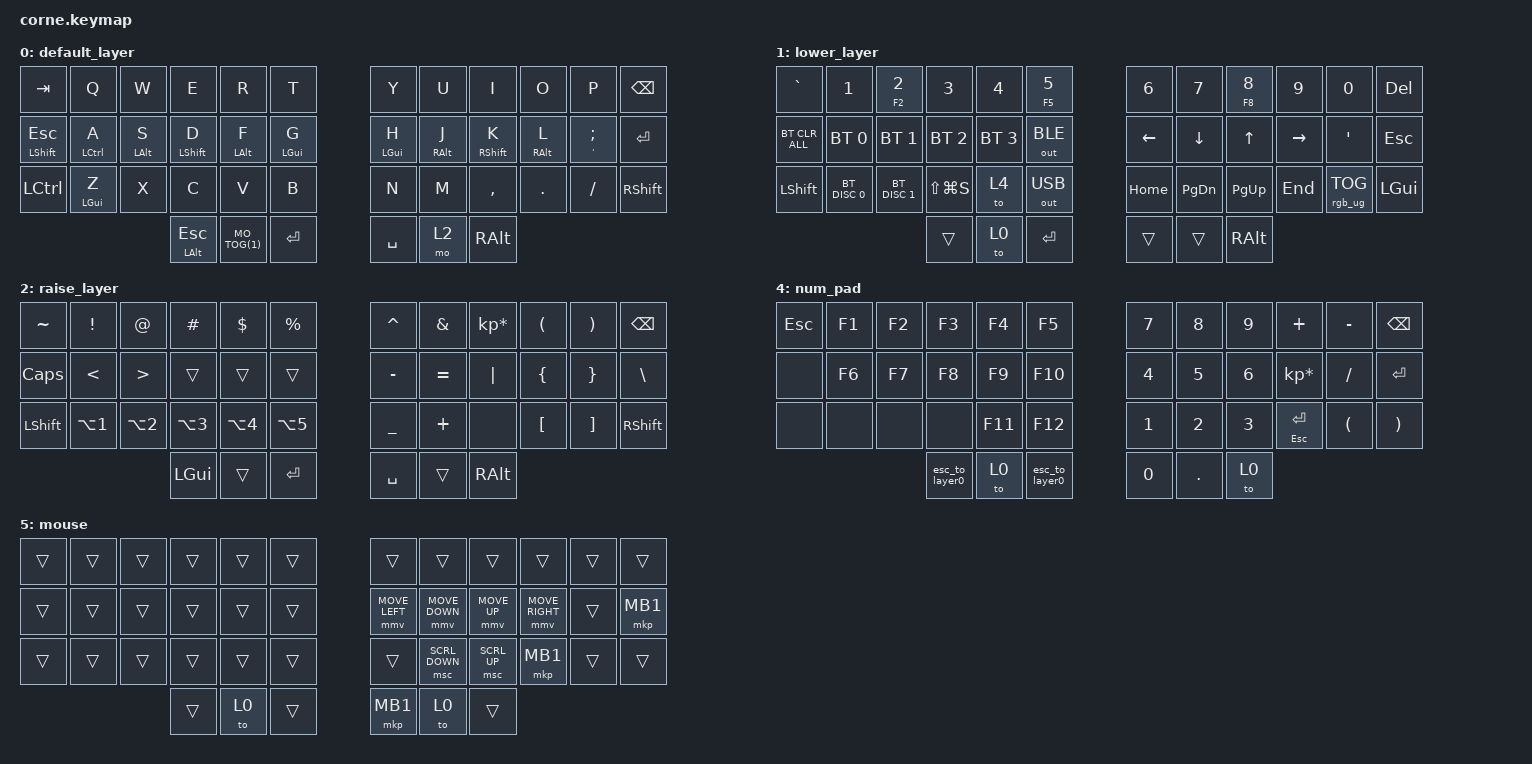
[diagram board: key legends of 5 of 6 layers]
/*
 * Copyright (c) 2020 The ZMK Contributors
 *
 * SPDX-License-Identifier: MIT
 */

#define ZMK_POINTING_DEFAULT_MOVE_VAL 1500  // default: 600
#define ZMK_POINTING_DEFAULT_SCRL_VAL 35    // default: 10

#include <behaviors.dtsi>
#include <dt-bindings/zmk/bt.h>
#include <dt-bindings/zmk/ext_power.h>
#include <dt-bindings/zmk/keys.h>
#include <dt-bindings/zmk/outputs.h>
#include <dt-bindings/zmk/pointing.h>
#include <dt-bindings/zmk/rgb.h>

#define MO_TOG(layer) &mo_tog layer layer   // Macro to apply momentary-layer-on-hold/toggle-layer-on-tap to a specific layer


&led_strip { chain-length = <27>; };

/ {
    behaviors {
        hm: homerow_mods {
            compatible = "zmk,behavior-hold-tap";
            #binding-cells = <2>;
            tapping-term-ms = <195>;
            quick-tap-ms = <100>;
            require-prior-idle-ms = <225>;
            flavor = "balanced";
            hold-trigger-on-release;
            bindings = <&kp>, <&kp>;
        };

        mo_tog: behavior_mo_tog {
            compatible = "zmk,behavior-hold-tap";
            #binding-cells = <2>;
            flavor = "hold-preferred";
            tapping-term-ms = <200>;
            bindings = <&mo>, <&tog>;
        };
                // &mo_tog 2 1     // &mo 2 on hold, &tog 1 on tap
                // MO_TOG(3)       // &mo 3 on hold, &tog 3 on tap
    };

    combos {
        compatible = "zmk,combos";

        controlLayer {
            bindings = <&to 3>;
            key-positions = <37 40>;
            timeout-ms = <250>;
        };

        to_num_pad {
            bindings = <&to 4>;
            key-positions = <36 2>;
        };

        print_screen {
            bindings = <&kp LS(LG(S))>;
            key-positions = <36 14>;
            layers = <0>;
        };

        escapeOnDefault {
            bindings = <&kp ESC>;
            key-positions = <39 23>;
            layers = <0>;
        };

        resr {
            bindings = <&print_seq>;
            key-positions = <36 15>;
        };

        to_mouse {
            bindings = <&to 5>;
            key-positions = <13 14>;
        };
    };

    macros {
        print_seq: print_seq_node {
            compatible = "zmk,behavior-macro";
            #binding-cells = <0>;
            bindings =
                <&macro_press>,
                <&kp LEFT_ALT &kp S>,
                <&macro_release>,
                <&kp LEFT_ALT>,
                <&macro_press>;

            label = "NEW_MACRO";
        };

        esc_to_layer0: esc_to_layer0 {
            compatible = "zmk,behavior-macro";
            #binding-cells = <0>;
            bindings = <&kp ESC &to 0>;
            label = "ESC_TO_LAYER0";
        };
    };

    keymap {
        compatible = "zmk,keymap";

        default_layer {
            bindings = <
&kp TAB           &kp Q               &kp W       &kp E             &kp R       &kp T         &kp Y           &kp U       &kp I        &kp O       &kp P                       &kp BSPC
&hm LSHFT ESC     &hm LEFT_CONTROL A  &hm LALT S  &hm LSHFT D       &hm LALT F  &hm LGUI G    &hm LEFT_GUI H  &hm RALT J  &hm RSHFT K  &hm RALT L  &mt SINGLE_QUOTE SEMICOLON  &kp RET
&kp LEFT_CONTROL  &hm LEFT_GUI Z      &kp X       &kp C             &kp V       &kp B         &kp N           &kp M       &kp COMMA    &kp DOT     &kp FSLH                    &kp RSHIFT
                                                  &mt LEFT_ALT ESC  MO_TOG(1)       &kp RET       &kp SPACE   &mo 2       &kp RALT
            >;
        };

        lower_layer {
            bindings = <
&kp GRAVE       &kp N1         &mt F2 NUMBER_2  &kp N3         &kp N4        &mt F5 N5       &kp N6    &kp N7         &mt F8 N8    &kp N9     &kp N0           &kp DELETE
&bt BT_CLR_ALL  &bt BT_SEL 0   &bt BT_SEL 1     &bt BT_SEL 2   &bt BT_SEL 3  &out OUT_BLE    &kp LEFT  &kp DOWN       &kp UP       &kp RIGHT  &kp SQT          &kp ESC
&kp LSHFT       &bt BT_DISC 0  &bt BT_DISC 1    &kp LS(LG(S))  &to 4         &out OUT_USB    &kp HOME  &kp PAGE_DOWN  &kp PAGE_UP  &kp END    &rgb_ug RGB_TOG  &kp LGUI
                                                &trans         &to 0         &kp RET         &trans    &trans         &kp RALT
            >;
        };

        raise_layer {
            bindings = <
&kp TILDE  &kp EXCL          &kp AT            &kp HASH          &kp DLLR          &kp PRCNT     &kp CARET  &kp AMPS   &kp KP_MULTIPLY  &kp LPAR          &kp RPAR           &kp BSPC
&kp CAPS   &kp LESS_THAN     &kp GREATER_THAN  &trans            &trans            &trans        &kp MINUS  &kp EQUAL  &kp PIPE         &kp LEFT_BRACE    &kp RIGHT_BRACE    &kp BACKSLASH
&kp LSHFT  &kp LA(NUMBER_1)  &kp LA(NUMBER_2)  &kp LA(NUMBER_3)  &kp LA(NUMBER_4)  &kp LA(N5)    &kp UNDER  &kp PLUS   &none            &kp LEFT_BRACKET  &kp RIGHT_BRACKET  &kp RIGHT_SHIFT
                                               &kp LGUI          &trans            &kp ENTER     &kp SPACE  &trans     &kp RALT
            >;
        };

        controls {
            bindings = <
&rgb_ug RGB_BRI  &rgb_ug RGB_COLOR_HSB(233,100,50)  &rgb_ug RGB_COLOR_HSB(0,98,51)    &out OUT_BLE  &bt BT_SEL 0   &bt BT_SEL 1     &ext_power EP_ON   &sys_reset      &to 5         &none  &kp C_BRIGHTNESS_INC  &kp C_VOLUME_UP
&rgb_ug RGB_BRD  &rgb_ug RGB_COLOR_HSB(164,97,51)   &rgb_ug RGB_COLOR_HSB(58,93,50)   &out OUT_USB  &bt BT_DISC 0  &bt BT_DISC 1    &ext_power EP_OFF  &msc SCRL_DOWN  &msc SCRL_UP  &none  &kp C_BRIGHTNESS_DEC  &kp C_VOLUME_DOWN
&rgb_ug RGB_TOG  &rgb_ug RGB_COLOR_HSB(0,94,39)     &rgb_ug RGB_COLOR_HSB(116,90,48)  &none         &none          &bt BT_CLR       &soft_off          &none           &none         &none  &none                 &kp C_MUTE
                                                                                      &none         &to 0          &none            &kp SPACE          &none           &none
            >;
        };

        num_pad {
            bindings = <
&kp ESC  &kp F1  &kp F2  &kp F3          &kp F4   &kp F5            &kp N7  &kp N8   &kp N9  &kp PLUS         &kp MINUS             &kp BACKSPACE
&none    &kp F6  &kp F7  &kp F8          &kp F9   &kp F10           &kp N4  &kp N5   &kp N6  &kp KP_MULTIPLY  &kp FSLH              &kp ENTER
&none    &none   &none   &none           &kp F11  &kp F12           &kp N1  &kp N2   &kp N3  &mt ESC ENTER    &kp LEFT_PARENTHESIS  &kp RPAR
                         &esc_to_layer0  &to 0    &esc_to_layer0    &kp N0  &kp DOT  &to 0
            >;
        };

        mouse {
            bindings = <
&trans  &trans  &trans  &trans  &trans  &trans    &trans          &trans          &trans        &trans           &trans  &trans
&trans  &trans  &trans  &trans  &trans  &trans    &mmv MOVE_LEFT  &mmv MOVE_DOWN  &mmv MOVE_UP  &mmv MOVE_RIGHT  &trans  &mkp MB1
&trans  &trans  &trans  &trans  &trans  &trans    &trans          &msc SCRL_DOWN  &msc SCRL_UP  &mkp MB1         &trans  &trans
                        &trans  &to 0   &trans    &mkp MB1        &to 0           &trans
            >;
        };
    };
};
